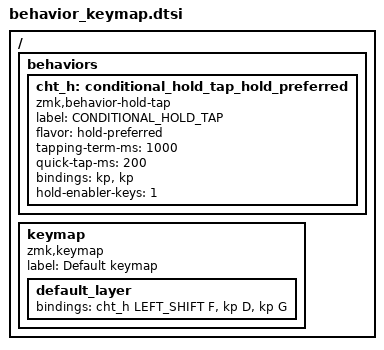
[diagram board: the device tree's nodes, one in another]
#include <dt-bindings/zmk/keys.h>
#include <behaviors.dtsi>
#include <dt-bindings/zmk/kscan_mock.h>

/ {
	behaviors {
		cht_h: conditional_hold_tap_hold_preferred {
			compatible = "zmk,behavior-hold-tap";
			label = "CONDITIONAL_HOLD_TAP";
			#binding-cells = <2>;
			flavor = "hold-preferred";
			tapping-term-ms = <1000>;
			quick-tap-ms = <200>;
			bindings = <&kp>, <&kp>;
			hold-enabler-keys = <1>;
		};
	};

	keymap {
		compatible = "zmk,keymap";
		label ="Default keymap";

		default_layer {
			bindings = <
				&cht_h LEFT_SHIFT F &kp D
				&kp G
			>;
		};
	};
};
